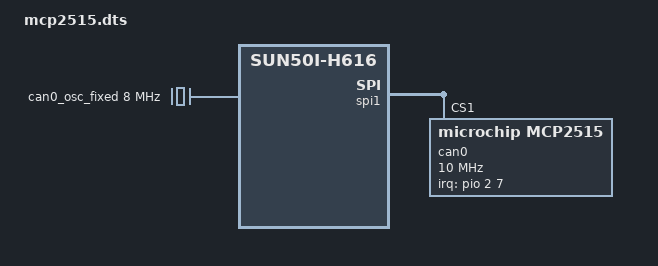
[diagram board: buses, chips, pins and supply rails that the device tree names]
/dts-v1/;
/plugin/;

/ {
    compatible = "xunlong,orangepi-zero3","allwinner,sun50i-h616";

    fragment@0 {
        target-path = "/";
        __overlay__ {
            can0_osc_fixed: can0_osc_fixed {
                compatible = "fixed-clock";
                #clock-cells = <0>;
                clock-frequency  = <8000000>;
            };
        };
    };

    fragment@1 {
        target = <&pio>;
        __overlay__ {
            can0_pin_irq: can0_pin_irq {
                pins = "PC7";
                function = "irq";
                bias-pull-up;
            };
        };
    };

    fragment@2 {
        target = <&spi1>;
        __overlay__ {
            #address-cells = <0x01>;
            #size-cells = <0x00>;
            status = "okay";
            can0: mcp2515@0 {
                reg = <1>;
                compatible = "microchip,mcp2515";
                pinctrl-names = "default";
                pinctrl-0 = <&can0_pin_irq>;
                spi-max-frequency = <10000000>;
                interrupt-parent = <&pio>;
                interrupts = <2 7 8>; /* PC7 IRQ_TYPE_EDGE_FALLING (should be 2 instead of 8)*/
                clocks = <&can0_osc_fixed>;
                status = "okay";
            };
        };
    };
};
